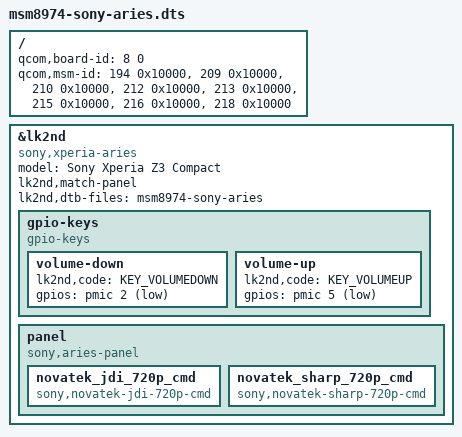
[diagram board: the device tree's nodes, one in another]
// SPDX-License-Identifier: GPL-2.0-only

/dts-v1/;

#include <skeleton32.dtsi>
#include <lk2nd.dtsi>

/ {
	qcom,board-id = <8 0>;
	qcom,msm-id = <194 0x10000>,
					<209 0x10000>,
					<210 0x10000>,
					<212 0x10000>,
					<213 0x10000>,
					<215 0x10000>,
					<216 0x10000>,
					<218 0x10000>;
};

&lk2nd {
	model = "Sony Xperia Z3 Compact";
	compatible = "sony,xperia-aries";
	/*
	 * Due to insufficient identification information in S1BOOT,
	 * we treat any device with the specified LCD panel as a Sony Xperia Z3 Compact (aries).
	 */
	lk2nd,match-panel;

	lk2nd,dtb-files = "msm8974-sony-aries";

	gpio-keys {
		compatible = "gpio-keys";

		volume-down {
			lk2nd,code = <KEY_VOLUMEDOWN>;
			gpios = <&pmic 2 (GPIO_ACTIVE_LOW | GPIO_PULL_UP)>;
		};

		volume-up {
			lk2nd,code = <KEY_VOLUMEUP>;
			gpios = <&pmic 5 (GPIO_ACTIVE_LOW | GPIO_PULL_UP)>;
		};
	};

	panel {
		compatible = "sony,aries-panel", "lk2nd,panel";

		novatek_jdi_720p_cmd {
			compatible = "sony,novatek-jdi-720p-cmd";
		};

		novatek_sharp_720p_cmd {
			compatible = "sony,novatek-sharp-720p-cmd";
		};
	};
};

#include "sony/msm8974pro-ac-shinano_aries_display.dtsi"
